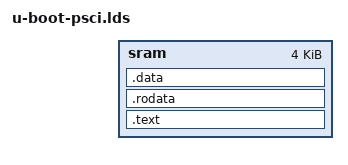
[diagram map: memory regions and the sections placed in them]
/*
 * (C) Copyright 2013 ARM Ltd
 * Marc Zyngier <marc.zyngier@arm.com>
 *
 * Based on sunxi/u-boot-spl.lds:
 *
 * (C) Copyright 2012
 * Allwinner Technology Co., Ltd. <www.allwinnertech.com>
 * Tom Cubie <tangliang@allwinnertech.com>
 *
 * Based on omap-common/u-boot-spl.lds:
 *
 * (C) Copyright 2002
 * Gary Jennejohn, DENX Software Engineering, <garyj@denx.de>
 *
 * (C) Copyright 2010
 * Texas Instruments, <www.ti.com>
 *	Aneesh V <aneesh@ti.com>
 *
 * See file CREDITS for list of people who contributed to this
 * project.
 *
 * This program is free software; you can redistribute it and/or
 * modify it under the terms of the GNU General Public License as
 * published by the Free Software Foundation; either version 2 of
 * the License, or (at your option) any later version.
 *
 * This program is distributed in the hope that it will be useful,
 * but WITHOUT ANY WARRANTY; without even the implied warranty of
 * MERCHANTABILITY or FITNESS FOR A PARTICULAR PURPOSE. See the
 * GNU General Public License for more details.
 *
 * You should have received a copy of the GNU General Public License
 * along with this program; if not, write to the Free Software
 * Foundation, Inc., 59 Temple Place, Suite 330, Boston,
 * MA 02111-1307 USA
 */

MEMORY { sram : ORIGIN = CONFIG_ARMV7_PSCI_BASE, LENGTH = 0x1000 }
OUTPUT_FORMAT("elf32-littlearm", "elf32-littlearm", "elf32-littlearm")
OUTPUT_ARCH(arm)
ENTRY(_start)
SECTIONS
{
	.text      :
	{
		_start = .;
		*(.text*)
	} > sram

	. = ALIGN(4);
	.rodata : { *(SORT_BY_ALIGNMENT(.rodata*)) } > sram

	. = ALIGN(4);
	.data : { *(SORT_BY_ALIGNMENT(.data*)) } > sram

	. = ALIGN(4);
	_end = .;

	/DISCARD/ : {
		*(.bss*)
	}
}
